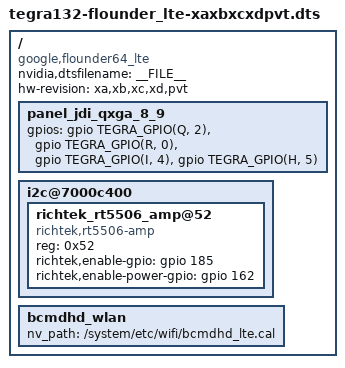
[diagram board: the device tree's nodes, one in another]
/dts-v1/;

#include "tegra132-flounder-generic.dtsi"

/ {
	compatible = "google,flounder64_lte", "nvidia,tegra132", "nvidia,tn8";
	nvidia,dtsfilename = __FILE__;
	hw-revision = "xa,xb,xc,xd,pvt";

        panel_jdi_qxga_8_9 {
                gpios = <&gpio TEGRA_GPIO(Q, 2) 0>,
                        <&gpio TEGRA_GPIO(R, 0) 0>,
                        <&gpio TEGRA_GPIO(I, 4) 0>,
                        <&gpio TEGRA_GPIO(H, 5) 0>;
        };
	i2c@7000c400 {
		richtek_rt5506_amp@52 {
			compatible = "richtek,rt5506-amp";
			reg = <0x52>;
			richtek,enable-gpio = <&gpio 185 0>;
			richtek,enable-power-gpio = <&gpio 162 0>;
		};
	};

	bcmdhd_wlan {
		nv_path = "/system/etc/wifi/bcmdhd_lte.cal";
	};
};

